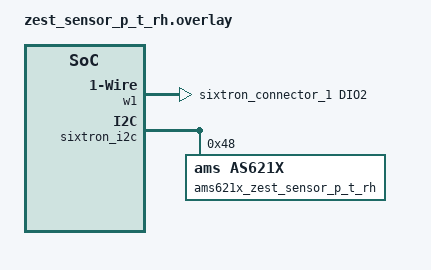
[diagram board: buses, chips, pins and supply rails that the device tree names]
/*
 * Copyright (c) 2024 CATIE
 *
 * SPDX-License-Identifier: Apache-2.0
 */

#include <zephyr/dt-bindings/gpio/sixtron-header.h>

/ {
	w1: w1 {
		compatible = "zephyr,w1-gpio";
		gpios = <&sixtron_connector_1 DIO2 (GPIO_ACTIVE_HIGH | GPIO_OPEN_DRAIN | GPIO_PULL_UP)>;
	};

	aliases {
		ams621x = &ams621x_zest_sensor_p_t_rh;
	};
};

&sixtron_i2c {
	status = "okay";

	ams621x_zest_sensor_p_t_rh: as621x@48 {
		compatible = "ams,as621x";
		reg = <0x48>;
	};
};
